# mcr_me30 register map
Registers are access not given, no defined reset value unless marked. A register's access mark holds for its fields unless they carry their own. Offsets are from the block's base; lines under a group give offsets from that group; [hi:lo] are bit positions; {n}, {i} and the like mark numbered series; 'fields as' and 'values as' point back to an identical list; <NAME> marks a mode.

## Memory map
0x40006C00 MCR size 0x400 — Misc Control.

## MCR — Misc Control.
Base 0x40006C00
0x04 RST wo — Reset Register.
  [0] BOOST — Reset BOOST Controller. Write 1 to reset; self-clearing. Register has no read path.
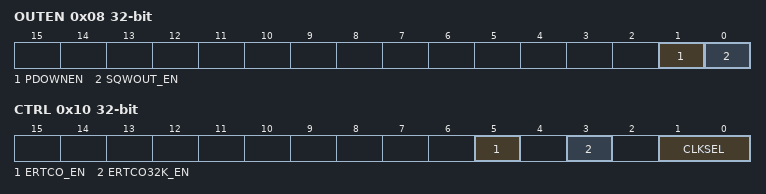
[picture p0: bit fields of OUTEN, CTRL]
0x08 OUTEN — Output Enable Register.
  [1] PDOWNEN — Power Down Enable (vestigial, not connected to functional logic).
  [0] SQWOUT_EN — Square Wave Output Enable.
0x10 CTRL — Control Register
  [5] ERTCO_EN — Enable the ERTCO.
  [3] ERTCO32K_EN — Enable the 32KHz ERTCO.
  [1:0] CLKSEL — Clock Select for the RTC, System, WUT, and Timer.
    0=ERTCO (ERTCO as clock source.); 1=INRO_DIV4 (INRO as clock source.); 2=RTC_IN (P0.12 CLK_EXT (undivided) as 32kHz clock source.)
0x30 BYPASS0 — This register is used by firmware to bypass chain of trust on a Warm Boot.
0x34 BYPASS1 — This register is used by firmware as a secondary bypass word for chain of trust on a Warm Boot.
0x40 DATA0 — Battery Back Data0 Register. Retains value in all modes.
0x44 DATA1 — Battery Back Data1 Register. Retains value in all modes.
